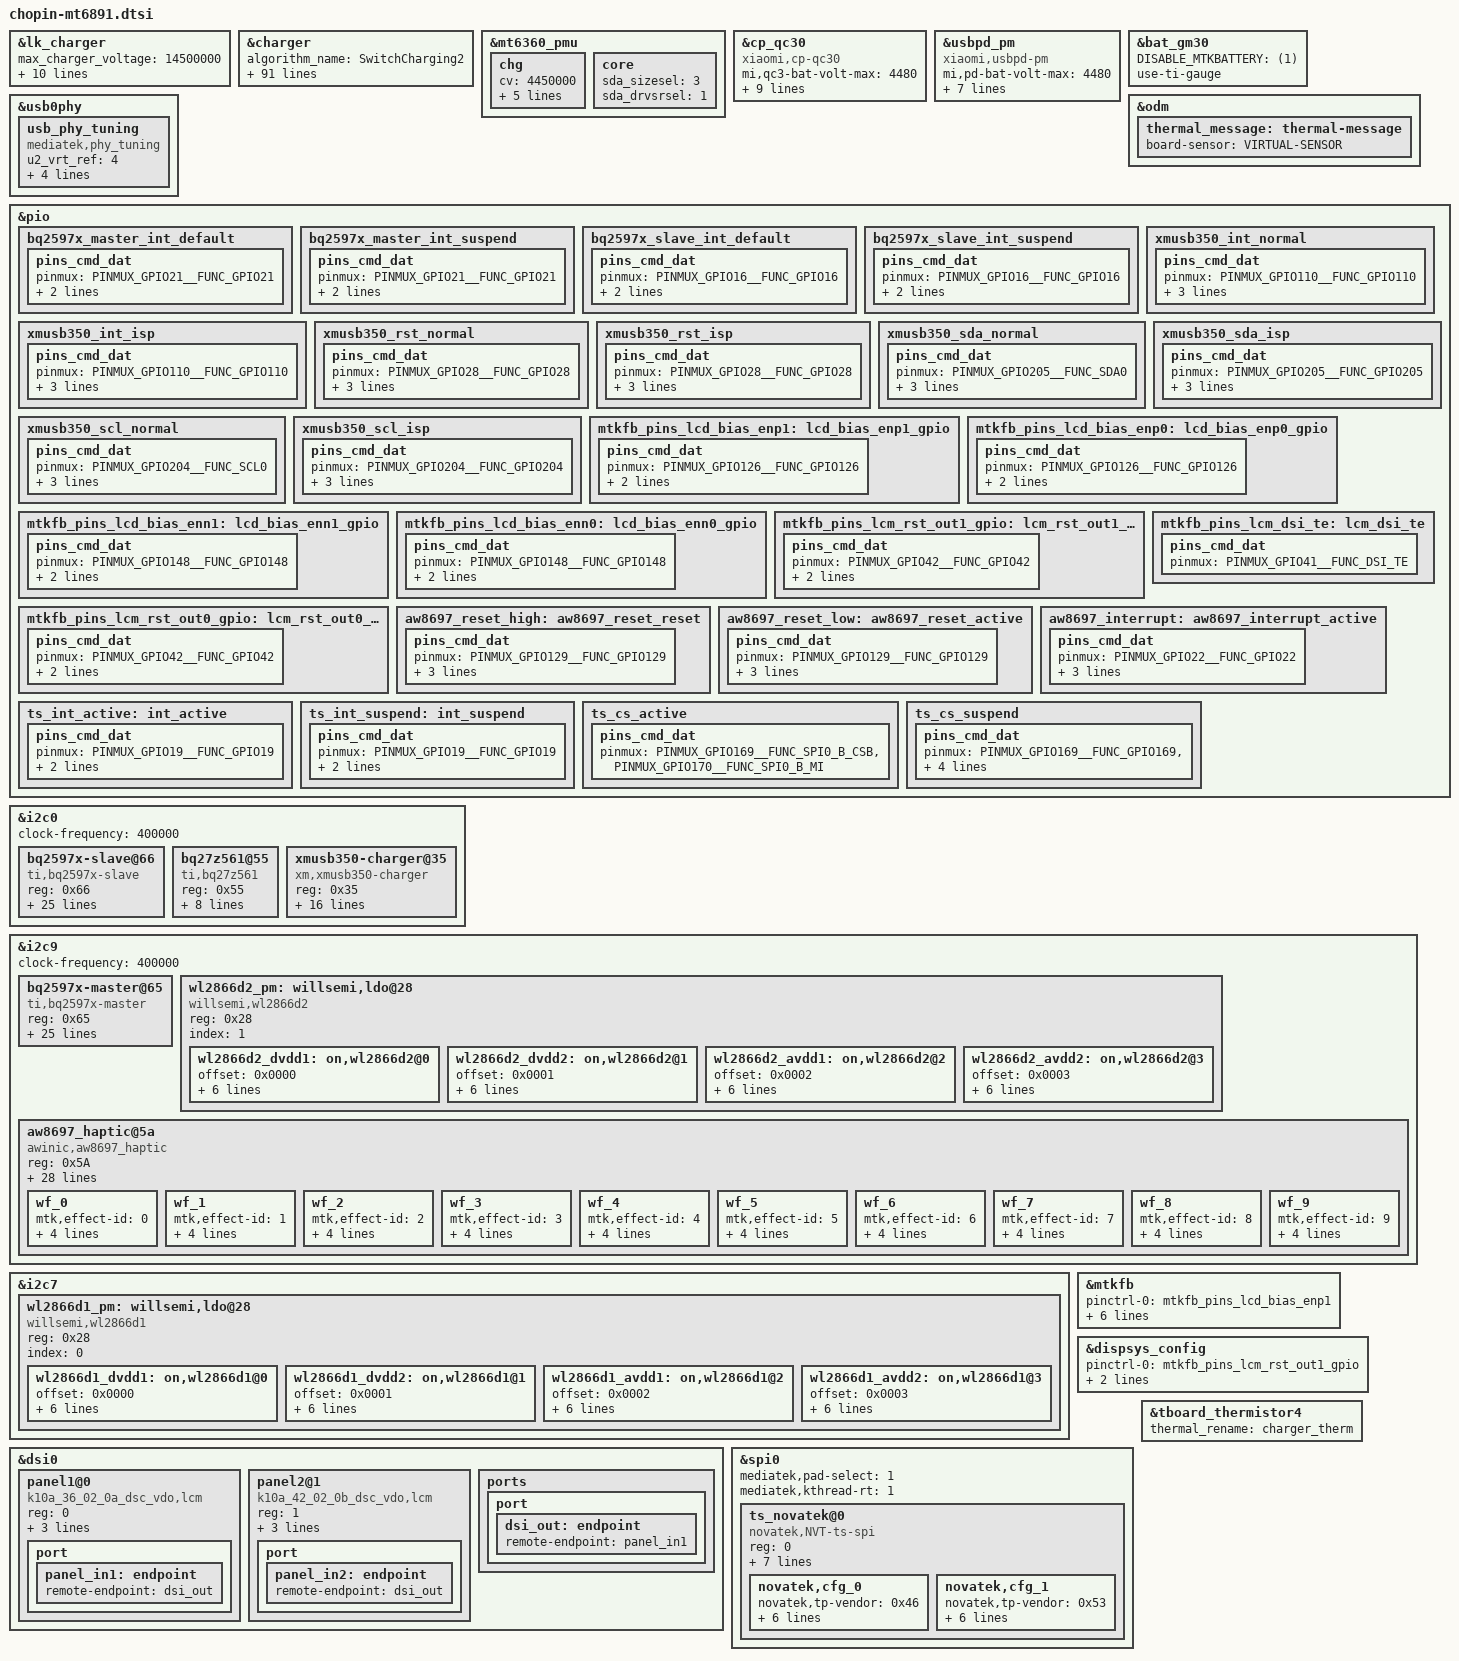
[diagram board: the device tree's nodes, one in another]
/*
this file is only for attribution of chopin
*/
#include "mediatek/xiaomi-mt6891-common.dtsi"

&lk_charger {
	max_charger_voltage = <14500000>;

	/* charging current */
	usb_charger_current = <500000>;
	ac_charger_current = <1500000>;
	ac_charger_input_current = <1500000>;
	non_std_ac_charger_current = <1000000>;
	charging_host_charger_current = <1500000>;
	ta_ac_charger_current = <1500000>;
	pd_charger_current = <1500000>;

	/* battery temperature protection */
	temp_t4_threshold = <60>;
	temp_t3_threshold = <0>;
	temp_t1_threshold = <(-10)>;
};

&charger {
	algorithm_name = "SwitchCharging2";

	battery_cv = <4460000>;

	/* vote */
	enable_vote;
	enable_cv_step;
	enable_cv_aging;
	step_a = <4200000>;
	step_b = <4300000>;
	step_c = <4400000>;
	current_a = <8937000>;
	current_b = <7447500>;
	current_c = <5958000>;
	current_max = <12400000>;
	step_hy_down_a = <150000>;
	step_hy_down_b = <150000>;
	step_hy_down_c = <150000>;
	step_a_aging = <4150000>;
	step_b_aging = <4300000>;
	step_c_aging = <4400000>;
	current_step_aging = <200000>;
	current_max_aging = <12400000>;

	/* ffc */
	enable_ffc;
	non_ffc_ieoc = <150000>;
	non_ffc_cv = <4450000>;
	ffc_ieoc = <700000>;
	ffc_ieoc_b = <850000>;
	ffc_cv = <4490000>;

	enable_sw_jeita;
	/* sw jeita */
	jeita_temp_above_t4_cv = <4100000>;
	jeita_temp_t3_to_t4_cv = <4100000>;
	jeita_temp_t2_to_t3_cv = <4450000>;
	jeita_temp_t1p5_to_t2_cv = <4450000>;
	jeita_temp_t1_to_t1p5_cv = <4450000>;
	jeita_temp_t0_to_t1_cv = <4450000>;
	jeita_temp_tn1_to_t0_cv_a = <4200000>;
	jeita_temp_tn1_to_t0_cv_b = <4450000>;
	jeita_temp_below_t0_cv = <4200000>;
	temp_t4_thres = <60>;
	temp_t4_thres_minus_x_degree = <58>;
	temp_t3_thres = <48>;
	temp_t3_thres_minus_x_degree = <47>;
	temp_t2_thres = <15>;
	temp_t2_thres_plus_x_degree = <17>;
	temp_t1p5_thres = <10>;
	temp_t1p5_thres_plus_x_degree = <11>;
	temp_t1_thres = <5>;
	temp_t1_thres_plus_x_degree = <6>;
	temp_t0_thres = <0>;
	temp_t0_thres_plus_x_degree = <1>;
	temp_tn1_thres = <(-10)>;
	temp_tn1_thres_plus_x_degree = <(-9)>;
	temp_neg_10_thres = <(-10)>;
	temp_t3_to_t4_fcc = <2500000>;
	temp_t2_to_t3_fcc = <12400000>;
	temp_t1p5_to_t2_fcc = <5958000>;
	temp_t1_to_t1p5_fcc = <3475500>;
	temp_t0_to_t1_fcc = <2500000>;
	temp_tn1_to_t0_fcc_a = <1000000>;
	temp_tn1_to_t0_fcc_b = <744750>;
	/* battery temperature protection */
	enable_min_charge_temp;
	min_charge_temp = <0>;
	min_charge_temp_plus_x_degree = <2>;
	max_charge_temp = <60>;
	max_charge_temp_minus_x_degree = <58>;

	qcom,thermal-mitigation-dcp
		= <1600000 1600000 1600000 1600000 1600000 1600000 1600000
		1600000 1600000 1600000 1600000 1600000 1500000 1400000
		1200000 1000000>;
	qcom,thermal-mitigation-qc3p5
		= <4500000 4200000 4000000 3800000 3600000 3400000 3200000
		3100000 3000000 2800000 2600000 2400000 2200000 2000000
		1000000 700000>;
	qcom,thermal-mitigation-qc3
		= <3500000 3500000 3500000 3400000 3300000 3300000 3200000
		3100000 3000000 2800000 2600000 2400000 2200000 2000000
		1000000 700000>;
	qcom,thermal-mitigation-qc3-classb
		= <5400000 5100000 4700000 4300000 4000000 3600000 3400000
		3400000 3400000 3200000 2500000 2200000 2000000 1300000
		1000000 700000>;
	qcom,thermal-mitigation-qc2
		= <1500000 1500000 1500000 1500000 1500000 1500000 1400000
		1300000 1200000 1100000 1000000 900000 800000 700000
		600000 500000>;
	qcom,thermal-mitigation-pd-base
		= <12400000 11000000 10000000 8000000 7000000 6000000 5500000
		5000000 4200000 3000000 2500000 1500000 1000000 800000
		500000 100000>;

	/* enable_pe_plus; */
	/* enable_pe_2; */
	bc12_charger = <1>;

	charging_host_charger_current = <1500000>;
	/* common */
	max_charger_voltage = <14500000>;

	/* xiaomi pps */
	xm_pps_single_charger_input_current = <3000000>;
	xm_pps_single_charger_current = <6000000>;
	xm_pps_dual_charger_input_current = <3000000>;
	xm_pps_dual_charger_chg1_current = <500000>;
	xm_pps_dual_charger_chg2_current = <2500000>;
	xm_pps_max_vbus = <12000000>;
	xm_pps_max_ibus = <3000000>;
	xm_pps_single_charger_current_non_verified_pps = <4800000>;

	/* PD */
	pd_vbus_upper_bound = <9000000>;
	ac_charger_input_current = <1500000>;
	/* float charger */
	non_std_ac_charger_current = <1000000>;
	/* default ac charger charge current */
	ac_charger_current = <2000000>;

	use_xmusb350_do_apsd;
};

&mt6360_pmu {
	chg {
		cv = <4450000>;			/* uA */
		ieoc = <200000>;		/* uA */
		ircmp_resistor = <0>;		/* uohm */
		ircmp_vclamp = <0>;		/* uV */
		en_te = <1>;
		en_eoc = <1>;
	};
	core {
		sda_sizesel = <3>;
		sda_drvsrsel = <1>;
	};
};

&cp_qc30 {
	compatible = "xiaomi,cp-qc30";
	status = "okay";
	mi,qc3-bat-volt-max = <4480>;
	mi,qc3-bat-curr-max = <3600>;
	mi,qc3-bus-volt-max = <12000>;
	mi,qc3-bus-curr-max = <2100>;
	mi,qc3-non-ffc-bat-volt-max = <4450>;

	mi,qc3-27w-bat-curr-max = <5400>;
	mi,qc3-27w-bus-curr-max = <2450>;
	mi,qc3p-bat-curr-max = <4500>;
	mi,qc3p-bus-curr-max = <2300>;
	mi,cp-sec-enable;
};

&usbpd_pm {
	compatible = "xiaomi,usbpd-pm";
	status = "okay";
	mi,pd-bat-volt-max = <4480>;
	mi,pd-bat-curr-max = <12400>;
	mi,pd-bus-volt-max = <12000>;
	mi,pd-bus-curr-max = <6200>;
	mi,pd-non-ffc-bat-volt-max = <4450>;
	mi,cp-sec-enable;
	mi,pd-power-max = <67>; /*charge power max : 67W */
	mi,cp-master-disable-fisrt;
};

&bat_gm30 {
	DISABLE_MTKBATTERY = <(1)>;
	use-ti-gauge;
};

&usb0phy {
	usb_phy_tuning {
		compatible = "mediatek,phy_tuning";
		u2_vrt_ref  = <4>;
		u2_term_ref = <4>;
		u2_enhance  = <1>;
		u2_intr_cal = <30>;
		u2_discth  = <7>;
	};
};

&odm {
	thermal_message: thermal-message {
		board-sensor = "VIRTUAL-SENSOR";
	};
};

&pio {
	/* bq25970-master */
	bq2597x_master_int_default: bq2597x_master_int_default {
		pins_cmd_dat {
			pinmux = <PINMUX_GPIO21__FUNC_GPIO21>;
			slew-rate = <0>;
			bias-pull-up = <11>;
		};
	};

	bq2597x_master_int_suspend: bq2597x_master_int_suspend {
		pins_cmd_dat {
			pinmux = <PINMUX_GPIO21__FUNC_GPIO21>;
			slew-rate = <0>;
			bias-pull-up = <11>;
		};
	};

	/* bq25970-slave */
	bq2597x_slave_int_default: bq2597x_slave_int_default {
		pins_cmd_dat {
			pinmux = <PINMUX_GPIO16__FUNC_GPIO16>;
			slew-rate = <0>;
			bias-pull-up = <11>;
		};
	};

	bq2597x_slave_int_suspend: bq2597x_slave_int_suspend {
		pins_cmd_dat {
			pinmux = <PINMUX_GPIO16__FUNC_GPIO16>;
			slew-rate = <0>;
			bias-pull-up = <11>;
		};
	};

	/* xmusb350 */
	xmusb350_int_normal: xmusb350_int_normal {
		pins_cmd_dat {
			pinmux = <PINMUX_GPIO110__FUNC_GPIO110>;
			slew-rate = <0>;
			bias-pull-up = <11>;
			input-enable;
		};
	};

	xmusb350_int_isp: xmusb350_int_isp {
		pins_cmd_dat {
			pinmux = <PINMUX_GPIO110__FUNC_GPIO110>;
			slew-rate = <0>;
			bias-pull-up = <11>;
			input-enable;
		};
	};

	xmusb350_rst_normal: xmusb350_rst_normal {
		pins_cmd_dat {
			pinmux = <PINMUX_GPIO28__FUNC_GPIO28>;
			slew-rate = <1>;
			bias-disable;
			output-low;
		};
	};

	xmusb350_rst_isp: xmusb350_rst_isp {
		pins_cmd_dat {
			pinmux = <PINMUX_GPIO28__FUNC_GPIO28>;
			slew-rate = <1>;
			bias-disable;
			output-low;
		};
	};

	xmusb350_sda_normal: xmusb350_sda_normal {
		pins_cmd_dat {
			pinmux = <PINMUX_GPIO205__FUNC_SDA0>;
			slew-rate = <0>;
			bias-pull-up;
			input-enable;
		};
	};

	xmusb350_sda_isp: xmusb350_sda_isp {
		pins_cmd_dat {
			pinmux = <PINMUX_GPIO205__FUNC_GPIO205>;
			slew-rate = <1>;
			bias-disable;
			output-low;
		};
	};

	xmusb350_scl_normal: xmusb350_scl_normal {
		pins_cmd_dat {
			pinmux = <PINMUX_GPIO204__FUNC_SCL0>;
			slew-rate = <0>;
			bias-pull-up;
			input-enable;
		};
	};

	xmusb350_scl_isp: xmusb350_scl_isp {
		pins_cmd_dat {
			pinmux = <PINMUX_GPIO204__FUNC_GPIO204>;
			slew-rate = <1>;
			bias-disable;
			output-low;
		};
	};
};

&i2c0 {
	clock-frequency = <400000>;

	bq2597x-slave@66 {
		compatible = "ti,bq2597x-slave";
		reg = <0x66>;
		interrupt-parent = <&pio>;
		interrupts = <16 IRQ_TYPE_EDGE_FALLING 16 0>;
		pinctrl-names = "bq2597x_slave_irq";
		pinctrl-0 = <&bq2597x_slave_int_default &bq2597x_slave_int_suspend>;

		charger_name = "quaternary_chg";

		//ti,bq2597x,bat-ovp-disable;
		//ti,bq2597x,bat-ovp-alarm-disable;
		//ti,bq2597x,bat-ocp-disable;
		//ti,bq2597x,bat-ocp-alarm-disable;
		ti,bq2597x,bat-ucp-alarm-disable;
		ti,bq2597x,bat-ucp-disable;

		//ti,bq2597x,bus-ovp-alarm-disable;
		//ti,bq2597x,bus-ocp-disable;
		//ti,bq2597x,bus-ocp-alarm-disable;
		ti,bq2597x,bat-therm-disable;
		ti,bq2597x,bus-therm-disable;
		ti,bq2597x,die-therm-disable;

		ti,bq2597x,bat-ovp-threshold = <4650>;
		ti,bq2597x,bat-ovp-alarm-threshold = <4625>;
		ti,bq2597x,bat-ocp-threshold = <7000>;
		ti,bq2597x,bat-ocp-alarm-threshold = <6000>;

		ti,bq2597x,bus-ovp-threshold = <12000>;
		ti,bq2597x,bus-ovp-alarm-threshold = <11000>;
		ti,bq2597x,bus-ocp-threshold = <3750>;
		ti,bq2597x,bus-ocp-alarm-threshold = <3500>;

		//ti,bq2597x,bat-ucp-alarm-threshold = <2000>;

		ti,bq2597x,bat-therm-threshold = <0x15>;/*4.1%*/
		ti,bq2597x,bus-therm-threshold = <0x15>;/*4.1%*/
		ti,bq2597x,die-therm-threshold = <145>;

		ti,bq2597x,ac-ovp-threshold = <14>;
		sc8551,ac-ovp-threshold = <13>;

		//ti,bq2597x,sense-resistor-mohm = <5>;
		sc8551,bypass-enable;
		sc8551a,dual-stdalone-scheme;
	};

	bq27z561@55 {
		compatible = "ti,bq27z561";
		reg = <0x55>;
		bq,ignore-digest-debug;
		bq,charge-full-design = <5000000>;
		bq,recharge-voltage   = <4380>;
		bq,shutdown-delay-enable;
		bq,soc_decimal_rate = <
			0  38
			10 35
			20 33
			30 33
			40 33
			50 33
			60 33
			70 30
			80 25
			90 20
			95 10 >;
		bq,cold_thermal_seq = <
			1      0  100 1700
			2  (-300)   0 1000 >;
	};

	xmusb350-charger@35 {
		compatible = "xm,xmusb350-charger";
		reg = <0x35>;
		interrupt-parent = <&pio>;
		interrupts = <110 IRQ_TYPE_EDGE_FALLING 110 0>;
		pinctrl-names = "xmusb350_normal", "xmusb350_isp";
		pinctrl-0 = <&xmusb350_rst_normal &xmusb350_sda_normal &xmusb350_scl_normal>;
		pinctrl-1 = <&xmusb350_rst_isp &xmusb350_sda_isp &xmusb350_scl_isp>;
		xm,xmusb350_rst_gpio = <&pio 28 0x00>;
		xm,xmusb350_sda_gpio = <&pio 205 0x00>;
		xm,xmusb350_scl_gpio = <&pio 204 0x00>;
		mi,connect_therm = <&pio 29 0x00>;

		charger_name = "secondary_chg";
		alias_name  = "xmusb350";
		en_bc12;
		en_hvdcp;
		en_intb;
		en_sleep;
	};
};

&i2c9 {
	clock-frequency = <400000>;

	bq2597x-master@65 {
		compatible = "ti,bq2597x-master";
		reg = <0x65>;
		interrupt-parent = <&pio>;
		interrupts = <21 IRQ_TYPE_EDGE_FALLING 21 0>;
		pinctrl-names = "bq2597x_master_irq";
		pinctrl-0 = <&bq2597x_master_int_default &bq2597x_master_int_suspend>;

		charger_name = "tertiary_chg";

		//ti,bq2597x,bat-ovp-disable;
		//ti,bq2597x,bat-ovp-alarm-disable;
		//ti,bq2597x,bat-ocp-disable;
		//ti,bq2597x,bat-ocp-alarm-disable;
		ti,bq2597x,bat-ucp-alarm-disable;
		ti,bq2597x,bat-ucp-disable;

		//ti,bq2597x,bus-ovp-alarm-disable;
		//ti,bq2597x,bus-ocp-disable;
		//ti,bq2597x,bus-ocp-alarm-disable;
		ti,bq2597x,bat-therm-disable;
		ti,bq2597x,bus-therm-disable;
		ti,bq2597x,die-therm-disable;

		ti,bq2597x,bat-ovp-threshold = <4650>;
		ti,bq2597x,bat-ovp-alarm-threshold = <4625>;
		ti,bq2597x,bat-ocp-threshold = <7000>;
		ti,bq2597x,bat-ocp-alarm-threshold = <6000>;

		ti,bq2597x,bus-ovp-threshold = <12000>;
		ti,bq2597x,bus-ovp-alarm-threshold = <11000>;
		//ti,bq2597x,bus-ocp-threshold = <2200>;
		//ti,bq2597x,bus-ocp-alarm-threshold = <2000>;
		ti,bq2597x,bus-ocp-threshold = <3750>;
		ti,bq2597x,bus-ocp-alarm-threshold = <3500>;

		//ti,bq2597x,bat-ucp-alarm-threshold = <2000>;

		ti,bq2597x,bat-therm-threshold = <0x15>;/*4.1%*/
		ti,bq2597x,bus-therm-threshold = <0x15>;/*4.1%*/
		ti,bq2597x,die-therm-threshold = <145>;

		ti,bq2597x,ac-ovp-threshold = <14>;
		sc8551,ac-ovp-threshold = <13>;

		//ti,bq2597x,sense-resistor-mohm = <5>;
		sc8551,bypass-enable;
		sc8551a,dual-stdalone-scheme;
	};
};

//WL2866D start
&i2c7 {
	wl2866d1_pm:willsemi,ldo@28 {
		compatible = "willsemi,wl2866d1";
		reg = <0x28>;/*slave address*/
		index = <0>;

		wl2866d1_dvdd1:on,wl2866d1@0{
			offset = /bits/ 16 <0x0000>;
			regulator-name ="wl2866d-dvdd1";
			regulator-min-microvolt = <600000>;
			regulator-max-microvolt = <1800000>;
			min-dropout-voltage = <80000>;
			iout_ua = <500000>;
			init-voltage = <1050000>;
		};

		wl2866d1_dvdd2:on,wl2866d1@1{
			offset = /bits/ 16 <0x0001>;
			regulator-name ="wl2866d-dvdd2";
			regulator-min-microvolt = <600000>;
			regulator-max-microvolt = <1800000>;
			min-dropout-voltage = <80000>;
			iout_ua = <500000>;
			init-voltage = <1200000>;
		};

		wl2866d1_avdd1:on,wl2866d1@2{
			offset = /bits/ 16 <0x0002>;
			regulator-name ="wl2866d-avdd1";
			regulator-min-microvolt = <1200000>;
			regulator-max-microvolt = <4300000>;
			min-dropout-voltage = <90000>;
			iout_ua = <300000>;
			init-voltage = <2800000>;
		};

		wl2866d1_avdd2:on,wl2866d1@3{
			offset = /bits/ 16 <0x0003>;
			regulator-name ="wl2866d-avdd2";
			regulator-min-microvolt = <1200000>;
			regulator-max-microvolt = <4300000>;
			min-dropout-voltage = <90000>;
			iout_ua = <300000>;
			init-voltage = <2800000>;
		};
	};
};

&i2c9 {
	wl2866d2_pm:willsemi,ldo@28 {
		compatible = "willsemi,wl2866d2";
		reg = <0x28>;/*slave address*/
		index = <1>;

		wl2866d2_dvdd1:on,wl2866d2@0{
			offset = /bits/ 16 <0x0000>;
			regulator-name ="wl2866d-dvdd1";
			regulator-min-microvolt = <600000>;
			regulator-max-microvolt = <1800000>;
			min-dropout-voltage = <80000>;
			iout_ua = <500000>;
			init-voltage = <1050000>;
		};

		wl2866d2_dvdd2:on,wl2866d2@1{
			offset = /bits/ 16 <0x0001>;
			regulator-name ="wl2866d-dvdd2";
			regulator-min-microvolt = <600000>;
			regulator-max-microvolt = <1800000>;
			min-dropout-voltage = <80000>;
			iout_ua = <500000>;
			init-voltage = <1300000>;
		};

		wl2866d2_avdd1:on,wl2866d2@2{
			offset = /bits/ 16 <0x0002>;
			regulator-name ="wl2866d-avdd1";
			regulator-min-microvolt = <1200000>;
			regulator-max-microvolt = <4300000>;
			min-dropout-voltage = <90000>;
			iout_ua = <300000>;
			init-voltage = <2800000>;
		};

		wl2866d2_avdd2:on,wl2866d2@3{
			offset = /bits/ 16 <0x0003>;
			regulator-name ="wl2866d-avdd2";
			regulator-min-microvolt = <1200000>;
			regulator-max-microvolt = <4300000>;
			min-dropout-voltage = <90000>;
			iout_ua = <300000>;
			init-voltage = <2800000>;
		};
	};
};
//WL2866D end

/* DISPSYS GPIO standardization */
&pio {
	mtkfb_pins_lcd_bias_enp1: lcd_bias_enp1_gpio {
		pins_cmd_dat {
			pinmux = <PINMUX_GPIO126__FUNC_GPIO126>;
			slew-rate = <1>;
			output-high;
		};
	};

	mtkfb_pins_lcd_bias_enp0: lcd_bias_enp0_gpio {
		pins_cmd_dat {
			pinmux = <PINMUX_GPIO126__FUNC_GPIO126>;
			slew-rate = <1>;
			output-low;
		};
	};

	mtkfb_pins_lcd_bias_enn1: lcd_bias_enn1_gpio {
		pins_cmd_dat {
			pinmux = <PINMUX_GPIO148__FUNC_GPIO148>;
			slew-rate = <1>;
			output-high;
		};
	};

	mtkfb_pins_lcd_bias_enn0: lcd_bias_enn0_gpio {
		pins_cmd_dat {
			pinmux = <PINMUX_GPIO148__FUNC_GPIO148>;
			slew-rate = <1>;
			output-low;
		};
	};

	mtkfb_pins_lcm_rst_out1_gpio: lcm_rst_out1_gpio {
		pins_cmd_dat {
			pinmux = <PINMUX_GPIO42__FUNC_GPIO42>;
			slew-rate = <1>;
			output-high;
		};
	};

	mtkfb_pins_lcm_rst_out0_gpio: lcm_rst_out0_gpio {
		pins_cmd_dat {
			pinmux = <PINMUX_GPIO42__FUNC_GPIO42>;
			slew-rate = <1>;
			output-low;
		};
	};

	mtkfb_pins_lcm_dsi_te: lcm_dsi_te {
		pins_cmd_dat {
			pinmux = <PINMUX_GPIO41__FUNC_DSI_TE>;
		};
	};
};

&mtkfb {
	pinctrl-names = "lcd_bias_enp1_gpio", "lcd_bias_enp0_gpio",
		"lcd_bias_enn1_gpio", "lcd_bias_enn0_gpio",
		"lcm_rst_out1_gpio", "lcm_rst_out0_gpio",
		"mode_te_te";
	pinctrl-0 = <&mtkfb_pins_lcd_bias_enp1>;
	pinctrl-1 = <&mtkfb_pins_lcd_bias_enp0>;
	pinctrl-2 = <&mtkfb_pins_lcd_bias_enn1>;
	pinctrl-3 = <&mtkfb_pins_lcd_bias_enn0>;
	pinctrl-4 = <&mtkfb_pins_lcm_rst_out1_gpio>;
	pinctrl-5 = <&mtkfb_pins_lcm_rst_out0_gpio>;
	pinctrl-6 = <&mtkfb_pins_lcm_dsi_te>;
	status = "okay";
};

&dispsys_config {
	pinctrl-names =
		"lcm_rst_out1_gpio", "lcm_rst_out0_gpio",
		"mode_te_te";
	pinctrl-0 = <&mtkfb_pins_lcm_rst_out1_gpio>;
	pinctrl-1 = <&mtkfb_pins_lcm_rst_out0_gpio>;
	pinctrl-2 = <&mtkfb_pins_lcm_dsi_te>;
	status = "okay";
};
/* DISPSYS GPIO standardization end */

&dsi0 {
	status = "okay";
	#address-cells = <1>;
	#size-cells = <0>;
	panel1@0 {
		compatible = "k10a_36_02_0a_dsc_vdo,lcm";
		reg = <0>;
		dvdd-supply = <&wl2866d2_dvdd2>;
		reset-gpios = <&pio 42 0>;
		bias-gpios = <&pio 126 0>,
			<&pio 148 0>;
		pinctrl-names = "default";
		port {
			panel_in1: endpoint {
				remote-endpoint = <&dsi_out>;
			};
		};
	};
	panel2@1 {
		compatible = "k10a_42_02_0b_dsc_vdo,lcm";
		reg = <1>;
		dvdd-supply = <&wl2866d2_dvdd2>;
		reset-gpios = <&pio 42 0>;
		bias-gpios = <&pio 126 0>,
			<&pio 148 0>;
		pinctrl-names = "default";
		port {
			panel_in2: endpoint {
				remote-endpoint = <&dsi_out>;
			};
		};
	};
	ports {
		port {
			dsi_out: endpoint {
				remote-endpoint = <&panel_in1>;
			};
		};
	};
};

/* AW8697 Haptic start */
&pio {
	aw8697_reset_high: aw8697_reset_reset {
		pins_cmd_dat {
			pinmux = <PINMUX_GPIO129__FUNC_GPIO129>;
			drive-strength = <2>;
			bias-disable;
			output-high;
		};
	};
	aw8697_reset_low: aw8697_reset_active {
		pins_cmd_dat {
			pinmux = <PINMUX_GPIO129__FUNC_GPIO129>;
			drive-strength = <2>;
			bias-disable;
			output-low;
		};
	};
	aw8697_interrupt: aw8697_interrupt_active {
		pins_cmd_dat {
			pinmux = <PINMUX_GPIO22__FUNC_GPIO22>;
			drive-strength = <2>;
			bias-pull-up;
			input-enable;
		};
	};
};

&i2c9 {
	status = "ok";
	aw8697_haptic@5a {
		compatible = "awinic,aw8697_haptic";
		reg = <0x5A>;
		reset-gpio = <&pio 129 0>;
		irq-gpio = <&pio 22 0>;
		vib_mode = < 0 >;   /*mode:   RAM mode->0; CONT mode -> 1*/
		vib_f0_pre = < 1700 >;
		vib_f0_cali_percen = < 7 >;
		vib_cont_drv_lev = < 60 >;
		vib_cont_drv_lvl_ov = < 60 >;
		vib_cont_td = < 0xef >;
		vib_cont_zc_thr = < 0x08f8 >;  /*hq 0x08F8 */
		vib_cont_num_brk = < 3 >;
		vib_f0_coeff = < 260 >; /*Don't modify it    2.604167*/
		vib_f0_trace_parameter = < 0x05 0x03 0x02 0x0f >;
		vib_bemf_config = < 0 0x08 0x03 0xf8 >;
		vib_sw_brake = < 0x2c >;
		vib_tset = < 0x1a >;
		vib_r_spare = < 0x68 >;
		vib_bstdbg = < 0x30 0xeb 0xd4 0 0 0 >;
		vib_effect_id_boundary = < 10 >;
		vib_effect_max = < 197 >;   /*vib_effect_max must bigger than vib_effect_id*/
		vib_trig_config = < 0 1 0 1 2
						0 1 0 1 2
						0 1 0 1 2 >;
		vib_bst_vol_default = < 0x0f >;
		vib_bst_vol_ram = < 0x0f >;
		vib_bst_vol_rtp = < 0x0f >;
		vib_rtp_time = < 20 20 20 20 20 20 20 20 20000 15000
				 15000 20000 25000 15000 30000 25000 20000 20000 20000 20000
				 20000 20000 20000 20000 20000 20000 20000 20000 20000 20000
				 20000 20000 20000 20000 20000 20000 20000 20000 20000 20000
				 20000 20000 20000 20000 20000 20000 20000 20000 20000 20000
				 20000 20000 20000 20000 20000 20000 20000 20000 20000 20000
				 20000 20000 20000 20000 20000 20000 20000 20000 20000 20000
				 20000 20000 20000 20000 20000 20000 20000 20000 20000 20000
				 20000 20000 20000 20000 20000 20000 20000 20000 20000 20000
				 20000 20000 20000 20000 20000 20000 20000 20000 20000 20000
				 20000 20000 20000 20000 20000 20000 20000 20000 20000 20000
				 20000 20000 20000 20000 20000 20000 20000 20000 20000 20000
				 20000 20000 20000 20000 20000 20000 20000 20000 20000 20000
				 20000 20000 20000 20000 20000 20000 20000 20000 20000 20000
				 20000 20000 20000 20000 20000 20000 20000 20000 20000 20000
				 20000 20000 20000 20000 20000 20000 20000 20000 20000 20000
				 20000 20000 20000 20000 20000 20000 20000 20000 20000 20000
				 20000 20000 20000 20000 20000 >;
		pinctrl-names = "aw8697_reset_reset","aw8697_reset_active","aw8697_interrupt_active";
		pinctrl-0 = <&aw8697_reset_low>;
		pinctrl-1 = <&aw8697_reset_high>;
		pinctrl-2 = <&aw8697_interrupt>;
		status = "ok";
		wf_0 {
			/*CLICK*/
			mtk,effect-id = <0>;
			mtk,wf-vmax-mv = <3600>;
			mtk,wf-pattern = [3e 3e];
			mtk,wf-brake-pattern = [02 01 00 00];
			mtk,wf-play-rate-us = <20000>;
		};
		wf_1 {
			/*DOUBLE CLICK*/
			mtk,effect-id = <1>;
			mtk,wf-vmax-mv = <3600>;
			mtk,wf-pattern = [7e 3e];
			mtk,wf-brake-pattern = [03 01 00 00];
			mtk,wf-play-rate-us = <20000>;
		};
		wf_2 {
			/*TICK*/
			mtk,effect-id = <2>;
			mtk,wf-vmax-mv = <3600>;
			mtk,wf-pattern = [7e 3e];
			mtk,wf-brake-pattern = [02 01 00 00];
			mtk,wf-play-rate-us = <20000>;
		};
		wf_3 {
			/*THUD*/
			mtk,effect-id = <3>;
			mtk,wf-vmax-mv = <3600>;
			mtk,wf-pattern = [3e 3e];
			mtk,wf-brake-pattern = [02 01 00 00];
			mtk,wf-play-rate-us = <20000>;
		};
		wf_4 {
			/*POP*/
			mtk,effect-id = <4>;
			mtk,wf-vmax-mv = <3600>;
			mtk,wf-pattern = [3e 3e];
			mtk,wf-brake-pattern = [02 01 00 00];
			mtk,wf-play-rate-us = <28000>;
		};
		wf_5 {
			/*HEAVY CLICK*/
			mtk,effect-id = <5>;
			mtk,wf-vmax-mv = <3600>;
			mtk,wf-pattern = [7e 7e 7e];
			mtk,wf-brake-pattern = [03 03 01 00];
			mtk,wf-play-rate-us = <20000>;
		};
		wf_6 {
			/*id 6*/
			mtk,effect-id = <6>;
			mtk,wf-vmax-mv = <3600>;
			mtk,wf-pattern = [3e 3e];
			mtk,wf-brake-pattern = [02 01 00 00];
			mtk,wf-play-rate-us = <20000>;
		};
		wf_7 {
			/*id 7*/
			mtk,effect-id = <7>;
			mtk,wf-vmax-mv = <3600>;
			mtk,wf-pattern = [3e 3e];
			mtk,wf-brake-pattern = [02 01 00 00];
			mtk,wf-play-rate-us = <20000>;
		};
		wf_8 {
			/*id 8*/
			mtk,effect-id = <8>;
			mtk,wf-vmax-mv = <3600>;
			mtk,wf-pattern = [3e 3e];
			mtk,wf-brake-pattern = [02 01 00 00];
			mtk,wf-play-rate-us = <20000>;
		};
		wf_9 {
			/*id 9*/
			mtk,effect-id = <9>;
			mtk,wf-vmax-mv = <3600>;
			mtk,wf-pattern = [3e 3e];
			mtk,wf-brake-pattern = [02 01 00 00];
			mtk,wf-play-rate-us = <20000>;
		};
	};
};
/* AW8697 Haptic end */

/* TOUCH start */
/* Novatek device tree node */
&spi0 {
        #address-cells = <1>;
        #size-cells = <0>;
        status = "okay";
        mediatek,pad-select = <1>;
	mediatek,kthread-rt = <1>;
        ts_novatek@0 {
                compatible = "novatek,NVT-ts-spi";
                reg = <0>;
                status = "ok";
                spi-max-frequency = <9600000>;  /*4800000,9600000,15000000,19200000 10M*/
                /*novatek,reset-gpio = <&pio 21 0x00>;*/
                novatek,irq-gpio = <&pio 19 0x2001>;
                pinctrl-names = "pmx_ts_active", "pmx_ts_suspend";
                pinctrl-0 = <&ts_int_active &ts_cs_active>;
                pinctrl-1 = <&ts_int_suspend &ts_cs_suspend>;
                novatek,swrst-n8-addr = <0x03F0FE>;
                novatek,spi-rd-fast-addr = <0x03F310>;
                novatek,config-array-size = <2>;
                novatek,cfg_0 {
                        novatek,tp-vendor = <0x46>;
                        novatek,display-maker = <0x36>;
                        novatek,fw-name = "novatek_nt36672c_k10a_fw01.bin";
                        novatek,mp-name = "novatek_nt36672c_k10a_mp01.bin";
                        novatek,clicknum-file-name = "nvt+tianma";
                };
                novatek,cfg_1 {
                        novatek,tp-vendor = <0x53>;
                        novatek,display-maker = <0x42>;
                        novatek,fw-name = "novatek_nt36672c_k10a_fw02.bin";
                        novatek,mp-name = "novatek_nt36672c_k10a_mp02.bin";
                        novatek,clicknum-file-name = "nvt+csot";
                };
        };
};

&pio {
        ts_int_active: int_active {
                pins_cmd_dat {
                        pinmux = <PINMUX_GPIO19__FUNC_GPIO19>;
                        slew-rate = <0>;
                        bias-disable;
                        /*bias-pull-up = <11>;*/
                };
        };
        ts_int_suspend: int_suspend {
                pins_cmd_dat {
                        pinmux = <PINMUX_GPIO19__FUNC_GPIO19>;
                        slew-rate = <1>;
                        output-low;
                };
        };
	ts_cs_active: ts_cs_active {
		pins_cmd_dat {
			pinmux = <PINMUX_GPIO169__FUNC_SPI0_B_CSB>,
				 <PINMUX_GPIO170__FUNC_SPI0_B_MI>;
		 };
	 };
	ts_cs_suspend: ts_cs_suspend {
		pins_cmd_dat {
			pinmux = <PINMUX_GPIO169__FUNC_GPIO169>,
				 <PINMUX_GPIO170__FUNC_GPIO170>;
			slew-rate = <1>;
			bias-pull-down;
			output-low;
		};
	};

};
/* TOUCH end */

&tboard_thermistor4 {
	thermal_rename = "charger_therm";
};

